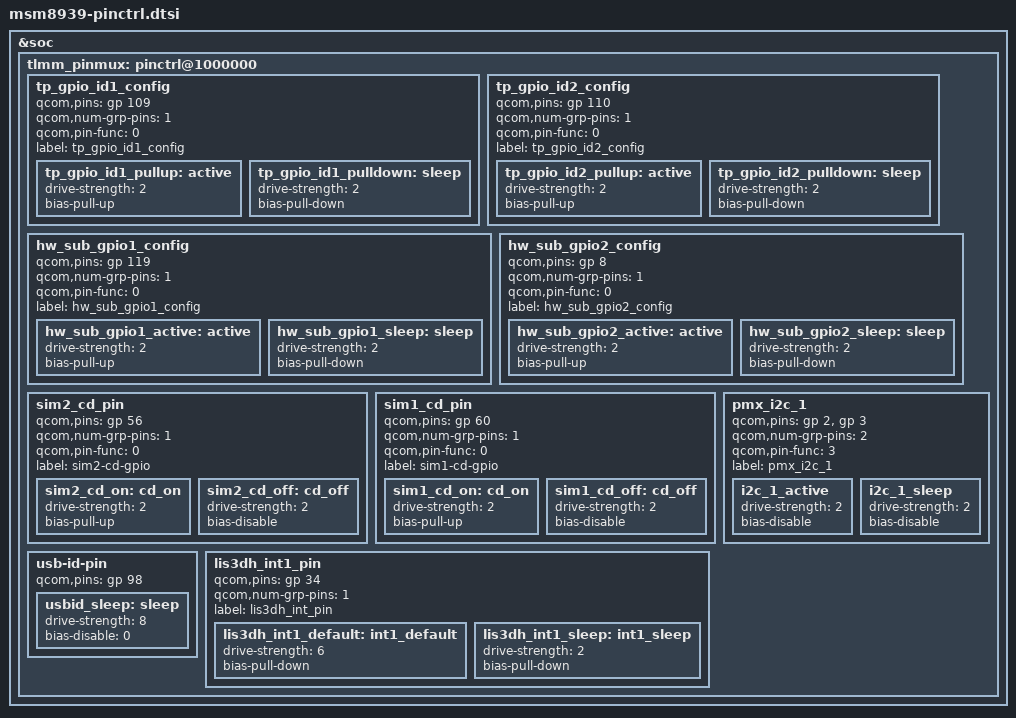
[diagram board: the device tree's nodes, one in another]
/* Copyright (c) 2014-2015, The Linux Foundation. All rights reserved.
 *
 * This program is free software; you can redistribute it and/or modify
 * it under the terms of the GNU General Public License version 2 and
 * only version 2 as published by the Free Software Foundation.
 *
 * This program is distributed in the hope that it will be useful,
 * but WITHOUT ANY WARRANTY; without even the implied warranty of
 * MERCHANTABILITY or FITNESS FOR A PARTICULAR PURPOSE.  See the
 * GNU General Public License for more details.
 */

#include "../msm8939-pinctrl.dtsi"

&soc {
	tlmm_pinmux: pinctrl@1000000 {
		tp_gpio_id1_config {
			qcom,pins = <&gp 109>;
			qcom,num-grp-pins = <1>;
			qcom,pin-func = <0>;
			label = "tp_gpio_id1_config";

			tp_gpio_id1_pullup: active {
				drive-strength = <2>;
				bias-pull-up;
			};

			tp_gpio_id1_pulldown: sleep {
				drive-strength = <2>;
				bias-pull-down;
			};
		};

		tp_gpio_id2_config {
			qcom,pins = <&gp 110>;
			qcom,num-grp-pins = <1>;
			qcom,pin-func = <0>;
			label = "tp_gpio_id2_config";

			tp_gpio_id2_pullup: active {
				drive-strength = <2>;
				bias-pull-up;
			};

			tp_gpio_id2_pulldown: sleep {
				drive-strength = <2>;
				bias-pull-down;
			};
		};

		hw_sub_gpio1_config {
			qcom,pins = <&gp 119>;
			qcom,num-grp-pins = <1>;
			qcom,pin-func = <0>;
			label = "hw_sub_gpio1_config";

			hw_sub_gpio1_active: active {
				drive-strength = <2>;
				bias-pull-up;
			};

			hw_sub_gpio1_sleep: sleep {
				drive-strength = <2>;
				bias-pull-down;
			};
		};

		hw_sub_gpio2_config {
			qcom,pins = <&gp 8>;
			qcom,num-grp-pins = <1>;
			qcom,pin-func = <0>;
			label = "hw_sub_gpio2_config";

			hw_sub_gpio2_active: active {
				drive-strength = <2>;
				bias-pull-up;
			};

			hw_sub_gpio2_sleep: sleep {
				drive-strength = <2>;
				bias-pull-down;
			};
		};

		sim2_cd_pin {
			qcom,pins = <&gp 56>;
			qcom,num-grp-pins = <1>;
			qcom,pin-func = <0>;
			label = "sim2-cd-gpio";

			sim2_cd_on: cd_on {
				drive-strength = <2>;
				bias-pull-up;
			};

			sim2_cd_off: cd_off {
				drive-strength = <2>;
				bias-disable;
			};
		};

		sim1_cd_pin {
			qcom,pins = <&gp 60>;
			qcom,num-grp-pins = <1>;
			qcom,pin-func = <0>;
			label = "sim1-cd-gpio";

			sim1_cd_on: cd_on {
				drive-strength = <2>;
				bias-pull-up;
			};

			sim1_cd_off: cd_off {
				drive-strength = <2>;
				bias-disable;
			};
		};

		pmx_i2c_1 {
			qcom,pins = <&gp 2>, <&gp 3>;
			qcom,num-grp-pins = <2>;
			qcom,pin-func = <3>;
			label = "pmx_i2c_1";

			i2c_1_active: i2c_1_active {
				drive-strength = <2>;
				bias-disable;
			};

			i2c_1_sleep: i2c_1_sleep {
				drive-strength = <2>;
				bias-disable;
			};
		};

		usb-id-pin {
			qcom,pins = <&gp 98>;

			usbid_sleep: sleep {
				drive-strength = <8>;
				bias-disable = <0>;
			};
		};

		lis3dh_int1_pin {
			qcom,pins = <&gp 34>;
			qcom,num-grp-pins = <1>;
			label = "lis3dh_int_pin";

			lis3dh_int1_default: int1_default {
				drive-strength = <6>;
				bias-pull-down;
			};

			lis3dh_int1_sleep: int1_sleep {
				drive-strength = <2>;
				bias-pull-down;
			};
		};
	};
};
